# STM32L4R7 register map
File version: 2.0
CPU: CM4 r0p1, little endian, MPU, FPU, 4 interrupt priority bits
Registers are 32-bit, read-write, reset 0x0 unless marked. A register's access mark holds for its fields unless they carry their own. Offsets are from the block's base; [hi:lo] are bit positions; {n}, {i} and the like mark numbered series.

## PWR — Power control
Base 0x40007000
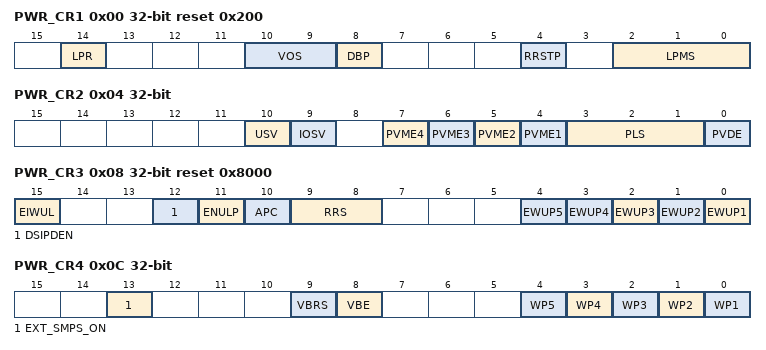
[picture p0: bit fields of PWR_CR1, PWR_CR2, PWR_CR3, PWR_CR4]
0x00 PWR_CR1 reset 0x200 — Power control register 1
  [14] LPR — Low-power run When this bit is set, the regulator is switched from main mode (MR) to low-power mode (LPR). Note: Stop 2 mode cannot be entered when LPR bit is set. Stop 1 is entered instead.
  [10:9] VOS — Voltage scaling range selection
    0=Cannot be written (forbidden by hardware); 1=Range 1; 2=Range 2; 3=Cannot be written (forbidden by hardware)
  [8] DBP — Disable backup domain write protection In reset state, the RTC and backup registers are protected against parasitic write access. This bit must be set to enable write access to these registers.
    0=Access to RTC and Backup registers disabled; 1=Access to RTC and Backup registers enabled
  [4] RRSTP — SRAM3 retention in Stop 2 mode
    0=SRAM3 is powered off in Stop 2 mode (SRAM3 content is lost); 1=SRAM3 is powered in Stop 2 mode (RAM3 content is kept)
  [2:0] LPMS — Low-power mode selection These bits select the low-power mode entered when CPU enters the Deepsleep mode. 1xx: Shutdown mode Note: If LPR bit is set, Stop 2 mode cannot be selected and Stop 1 mode shall be entered instead of Stop 2. Note: In Standby mode, SRAM2 can be preserved or not, depending on RRS bit configuration in PWR_CR3.
    0=Stop 0 mode; 1=Stop 1 mode; 2=Stop 2 mode; 3=Standby mode
0x04 PWR_CR2 — Power control register 2
  [10] USV — V<sub>DDUSB</sub> USB supply valid This bit is used to validate the V<sub>DDUSB</sub> supply for electrical and logical isolation purpose. Setting this bit is mandatory to use the USB OTG_FS peripheral. If V<sub>DDUSB</sub> is not always present in the application, the PVM can be used to determine whether this supply is ready or not.
    0=V<sub>DDUSB</sub> is not present. Logical and electrical isolation is applied to ignore this supply.; 1=V<sub>DDUSB</sub> is valid
  [9] IOSV — V<sub>DDIO2</sub> Independent I/Os supply valid This bit is used to validate the V<sub>DDIO2</sub> supply for electrical and logical isolation purpose. Setting this bit is mandatory to use PG[15:2]. If V<sub>DDIO2</sub> is not always present in the application, the PVM can be used to determine whether this supply is ready or not.
    0=V<sub>DDIO2</sub> is not present. Logical and electrical isolation is applied to ignore this supply.; 1=V<sub>DDIO2</sub> is valid
  [7] PVME4 — Peripheral voltage monitoring 4 enable: V<sub>DDA</sub> vs. 2.2V
    0=PVM4 (V<sub>DDA</sub> monitoring vs. 2.2V threshold) disable.; 1=PVM4 (V<sub>DDA</sub> monitoring vs. 2.2V threshold) enable.
  [6] PVME3 — Peripheral voltage monitoring 3 enable: V<sub>DDA</sub> vs. 1.62V
    0=PVM3 (V<sub>DDA</sub> monitoring vs. 1.62V threshold) disable.; 1=PVM3 (V<sub>DDA</sub> monitoring vs. 1.62V threshold) enable.
  [5] PVME2 — Peripheral voltage monitoring 2 enable: V<sub>DDIO2</sub> vs. 0.9V
    0=PVM2 (V<sub>DDIO2</sub> monitoring vs. 0.9V threshold) disable.; 1=PVM2 (V<sub>DDIO2</sub> monitoring vs. 0.9V threshold) enable.
  [4] PVME1 — Peripheral voltage monitoring 1 enable: V<sub>DDUSB</sub> vs. 1.2V
    0=PVM1 (V<sub>DDUSB</sub> monitoring vs. 1.2V threshold) disable.; 1=PVM1 (V<sub>DDUSB</sub> monitoring vs. 1.2V threshold) enable.
  [3:1] PLS — Power voltage detector level selection. These bits select the voltage threshold detected by the power voltage detector: Note: These bits are write-protected when the bit PVDL (PVD Lock) is set in the SYSCFG_CBR register. Note: These bits are reset only by a system reset.
    0=V<sub>PVD0</sub> around 2.0 V; 1=V<sub>PVD1</sub> around 2.2 V; 2=V<sub>PVD2</sub> around 2.4 V; 3=V<sub>PVD3</sub> around 2.5 V; 4=V<sub>PVD4</sub> around 2.6 V; 5=V<sub>PVD5</sub> around 2.8 V; 6=V<sub>PVD6</sub> around 2.9 V; 7=External input analog voltage PVD_IN (compared internally to VREFINT)
  [0] PVDE — Power voltage detector enable Note: This bit is write-protected when the bit PVDL (PVD Lock) is set in the SYSCFG_CBR register. Note: This bit is reset only by a system reset.
    0=Power voltage detector disable; 1=Power voltage detector enable
0x08 PWR_CR3 reset 0x8000 — Power control register 3
  [15] EIWUL — Enable internal wakeup line
    0=Internal wakeup line disable; 1=Internal wakeup line enable
  [12] DSIPDEN — Enable Pull-down activation on DSI pins
    1=Pull-Down is enabled on DSI pins; 0=Pull-Down is disabled on DSI pins
  [11] ENULP — Enable ULP sampling When this bit is set, the BORL, BORH and PVD are periodically sampled instead continuous monitoring to reduce power consumption. Fast supply drop between two sample/compare phases is not detected in this mode. This bit has impact only on STOP2, Standby and shutdown low power modes. Note: Available on STM32L4P5xx andSTM32L4Q5xx only.
  [10] APC — Apply pull-up and pull-down configuration When this bit is set, the I/O pull-up and pull-down configurations defined in the PWR_PUCRx and PWR_PDCRx registers are applied. When this bit is cleared, the PWR_PUCRx and PWR_PDCRx registers are not applied to the I/Os, instead the I/Os will be in floating mode during Standby or configured according GPIO controller GPIOx_PUPDR register during Run mode.
  [9:8] RRS — SRAM2 retention in Standby mode For STM32L4Rxxx and STM32L4Sxxx devices bit 9 is reserved For STM32L4P5xx and STM32L4Q5xx devices:
    0=SRAM2 is powered off in Standby mode (SRAM2 content is lost); 1=Full SRAM2 is powered by the low-power regulator in Standby mode (SRAM2 full content is kept); 2=Only 4 Kbytes of SRAM2 is powered by the low-power regulator in Standby mode (4 Kbytes of SRAM2 content is kept)
  [4] EWUP5 — Enable Wakeup pin WKUP5 When this bit is set, the external wakeup pin WKUP5 is enabled and triggers a wakeup from Standby or Shutdown event when a rising or a falling edge occurs.The active edge is configured via the WP5 bit in the PWR_CR4 register.
  [n-1] EWUP{n} (n=1..4) — Enable Wakeup pin WKUP{n} When this bit is set, the external wakeup pin WKUP{n} is enabled and triggers a wakeup from Standby or Shutdown event when a rising or a falling edge occurs. The active edge is configured via the WP{n} bit in the PWR_CR4 register.
0x0C PWR_CR4 — Power control register 4
  [13] EXT_SMPS_ON — external SMPS on. This bit informs the internal regulator about external SMPS switch status to decrease regulator output to 0.95 V in Range 2, allowing the external SMPS output down to 1.00 V. Note: This bit is only available on STM32L4P5xx and STM32L4Q5xx devices.
    0=the external SMPS switch is open; 1=the external SMPS switch is closed, internal regulator output is set to 0.95 V
  [9] VBRS — V<sub>BAT</sub> battery charging resistor selection
    0=Charge V<sub>BAT</sub> through a 5 kOhms resistor; 1=Charge V<sub>BAT</sub> through a 1.5 kOhms resistor
  [8] VBE — V<sub>BAT</sub> battery charging enable
    0=V<sub>BAT</sub> battery charging disable; 1=V<sub>BAT</sub> battery charging enable
  [n-1] WP{n} (n=1..5) — Wakeup pin WKUP{n} polarity This bit defines the polarity used for an event detection on external wake-up pin, WKUP{n}
    0=Detection on high level (rising edge); 1=Detection on low level (falling edge)
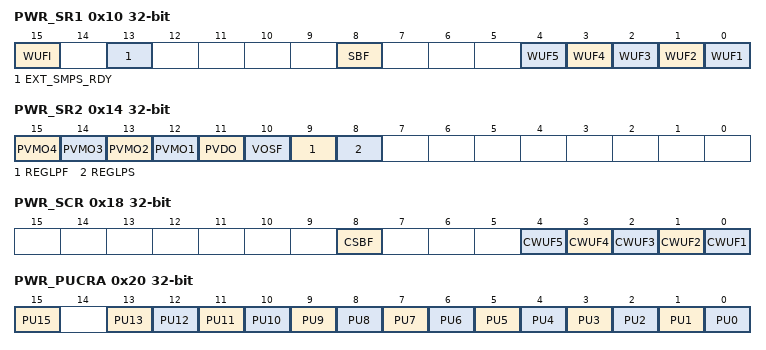
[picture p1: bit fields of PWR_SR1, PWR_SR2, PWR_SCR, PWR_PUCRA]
0x10 PWR_SR1 ro — Power status register 1
  [15] WUFI — Wakeup flag internal This bit is set when a wakeup is detected on the internal wakeup line. It is cleared when all internal wakeup sources are cleared.
  [13] EXT_SMPS_RDY — External SMPS ready This bit informs the state of regulator transition from Range 1 to Range 2 Note: This bit is only available on STM32L4P5xx and STM32L4Q5xx devices.
    0=Internal regulator not ready in Range 2, the external SMPS cannot be connected; 1=Internal regulator ready in Range 2, the external SMPS can be connected
  [8] SBF — Standby flag This bit is set by hardware when the device enters the Standby mode and is cleared by setting the CSBF bit in the PWR_SCR register, or by a power-on reset. It is not cleared by the system reset.
    0=The device did not enter the Standby mode; 1=The device entered the Standby mode
  [4] WUF5 — Wakeup flag 5 This bit is set when a wakeup event is detected on wakeup pin, WKUP5. It is cleared by writing 1 in the CWUF5 bit of the PWR_SCR register.
  [3] WUF4 — Wakeup flag 4 This bit is set when a wakeup event is detected on wakeup pin,WKUP4. It is cleared by writing 1 in the CWUF4 bit of the PWR_SCR register.
  [2] WUF3 — Wakeup flag 3 This bit is set when a wakeup event is detected on wakeup pin, WKUP3. It is cleared by writing 1 in the CWUF3 bit of the PWR_SCR register.
  [1] WUF2 — Wakeup flag 2 This bit is set when a wakeup event is detected on wakeup pin, WKUP2. It is cleared by writing 1 in the CWUF2 bit of the PWR_SCR register.
  [0] WUF1 — Wakeup flag 1 This bit is set when a wakeup event is detected on wakeup pin, WKUP1. It is cleared by writing 1 in the CWUF1 bit of the PWR_SCR register.
0x14 PWR_SR2 ro — Power status register 2
  [15] PVMO4 — Peripheral voltage monitoring output: V<sub>DDA</sub> vs. 2.2 V Note: PVMO4 is cleared when PVM4 is disabled (PVME4 = 0). After enabling PVM4, the PVM4 output is valid after the PVM4 wakeup time.
    0=V<sub>DDA</sub> voltage is above PVM4 threshold (around 2.2 V); 1=V<sub>DDA</sub> voltage is below PVM4 threshold (around 2.2 V)
  [14] PVMO3 — Peripheral voltage monitoring output: V<sub>DDA</sub> vs. 1.62 V Note: PVMO3 is cleared when PVM3 is disabled (PVME3 = 0). After enabling PVM3, the PVM3 output is valid after the PVM3 wakeup time.
    0=V<sub>DDA</sub> voltage is above PVM3 threshold (around 1.62 V); 1=V<sub>DDA</sub> voltage is below PVM3 threshold (around 1.62 V)
  [13] PVMO2 — Peripheral voltage monitoring output: V<sub>DDIO2</sub> vs. 0.9 V Note: PVMO2 is cleared when PVM2 is disabled (PVME2 = 0). After enabling PVM2, the PVM2 output is valid after the PVM2 wakeup time.
    0=V<sub>DDIO2</sub> voltage is above PVM2 threshold (around 0.9 V); 1=V<sub>DDIO2</sub> voltage is below PVM2 threshold (around 0.9 V)
  [12] PVMO1 — Peripheral voltage monitoring output: V<sub>DDUSB</sub> vs. 1.2 V Note: PVMO1 is cleared when PVM1 is disabled (PVME1 = 0). After enabling PVM1, the PVM1 output is valid after the PVM1 wakeup time.
    0=V<sub>DDUSB</sub> voltage is above PVM1 threshold (around 1.2 V); 1=V<sub>DDUSB</sub> voltage is below PVM1 threshold (around 1.2 V)
  [11] PVDO — Power voltage detector output
    0=V<sub>DD</sub> is above the selected PVD threshold; 1=V<sub>DD</sub> is below the selected PVD threshold
  [10] VOSF — Voltage scaling flag A delay is required for the internal regulator to be ready after the voltage scaling has been changed. VOSF indicates that the regulator reached the voltage level defined with VOS bits of the PWR_CR1 register.
    0=The regulator is ready in the selected voltage range; 1=The regulator output voltage is changing to the required voltage level
  [9] REGLPF — Low-power regulator flag This bit is set by hardware when the MCU is in Low-power run mode. When the MCU exits from the Low-power run mode, this bit remains at 1 until the regulator is ready in main mode. A polling on this bit must be done before increasing the product frequency. This bit is cleared by hardware when the regulator is ready.
    0=The regulator is ready in main mode (MR); 1=The regulator is in low-power mode (LPR)
  [8] REGLPS — Low-power regulator started This bit provides the information whether the low-power regulator is ready after a power-on reset or a Standby/Shutdown. If the Standby mode is entered while REGLPS bit is still cleared, the wakeup from Standby mode time may be increased.
    0=The low-power regulator is not ready; 1=The low-power regulator is ready
0x18 PWR_SCR wo — Power status clear register
  [8] CSBF — Clear standby flag Setting this bit clears the SBF flag in the PWR_SR1 register.
  [n-1] CWUF{n} (n=1..5) — Clear wakeup flag {n} Setting this bit clears the WUF{n} flag in the PWR_SR1 register.
0x20 PWR_PUCRA — Power Port A pull-up control register
  [15] PU15 — Port A pull-up bit 15 When set, this bit activates the pull-up on PA[15] when APC bit is set in PWR_CR3 register. If the corresponding PD15 bit is also set, the pull-up is not activated and the pull-down is activated instead with highest priority.
  [n] PU{n} (n=0..13) — Port A pull-up bit y (y=0...13) When set, this bit activates the pull-up on PA[y] when APC bit is set in PWR_CR3 register. The pull-up is not activated if the corresponding PDy bit is also set.
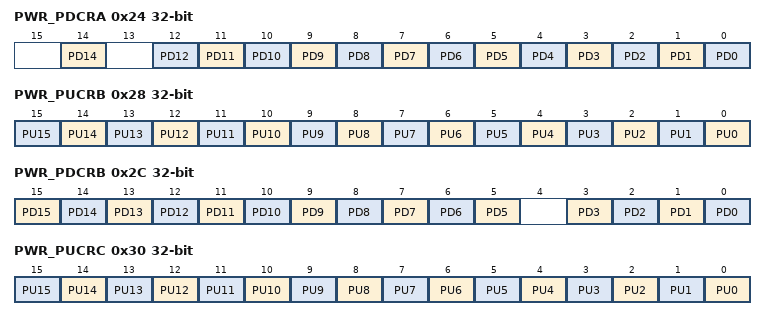
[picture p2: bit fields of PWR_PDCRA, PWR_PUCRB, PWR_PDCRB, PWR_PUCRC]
0x24 PWR_PDCRA — Power Port A pull-down control register
  [14] PD14 — Port A pull-down bit 14 When set, this bit activates the pull-down on PA[14] when APC bit is set in PWR_CR3 register.
  [n] PD{n} (n=0..12) — Port A pull-down bit y (y=0..12) When set, this bit activates the pull-down on PA[y] when APC bit is set in PWR_CR3 register.
0x28 PWR_PUCRB — Power Port B pull-up control register
  [n] PU{n} (n=0..15) — Port B pull-up bit y (y=0..15) When set, this bit activates the pull-up on PB[y] when APC bit is set in PWR_CR3 register. The pull-up is not activated if the corresponding PDy bit is also set.
0x2C PWR_PDCRB — Power Port B pull-down control register
  [n] PD{n} (n=5..15) — Port B pull-down bit y (y=5..15) When set, this bit activates the pull-down on PB[y] when APC bit is set in PWR_CR3 register.
  [n] PD{n} (n=0..3) — Port B pull-down bit y (y=0..3) When set, this bit activates the pull-down on PB[y] when APC bit is set in PWR_CR3 register.
0x30 PWR_PUCRC — Power Port C pull-up control register
  [n] PU{n} (n=0..15) — Port C pull-up bit y (y=0..15) When set, this bit activates the pull-up on PC[y] when APC bit is set in PWR_CR3 register. The pull-up is not activated if the corresponding PDy bit is also set.
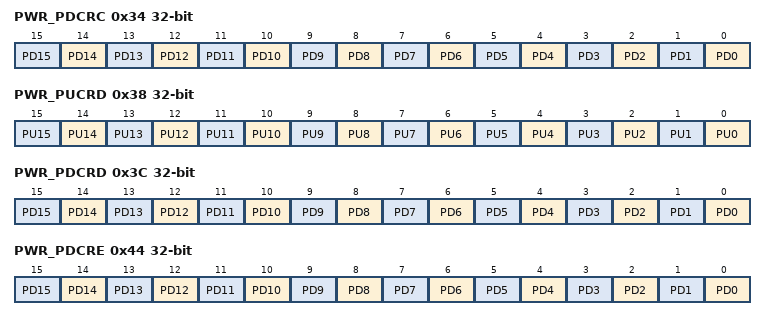
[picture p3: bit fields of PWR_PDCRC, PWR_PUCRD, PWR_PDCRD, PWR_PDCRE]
0x34 PWR_PDCRC — Power Port C pull-down control register
  [n] PD{n} (n=0..15) — Port C pull-down bit y (y=0..15) When set, this bit activates the pull-down on PC[y] when APC bit is set in PWR_CR3 register.
0x38 PWR_PUCRD — Power Port D pull-up control register
  [n] PU{n} (n=0..15) — Port D pull-up bit y (y=0..15) When set, this bit activates the pull-up on PD[y] when APC bit is set in PWR_CR3 register. The pull-up is not activated if the corresponding PDy bit is also set.
0x3C PWR_PDCRD — Power Port D pull-down control register
  [n] PD{n} (n=0..15) — Port D pull-down bit y (y=0..15) When set, this bit activates the pull-down on PD[y] when APC bit is set in PWR_CR3 register.
0x44 PWR_PDCRE — Power Port E pull-down control register
  [n] PD{n} (n=0..15) — Port E pull-down bit y (y=0..15) When set, this bit activates the pull-down on PE[y] when APC bit is set in PWR_CR3 register.
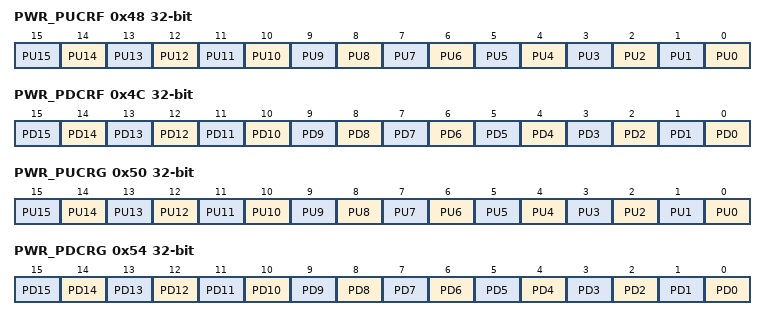
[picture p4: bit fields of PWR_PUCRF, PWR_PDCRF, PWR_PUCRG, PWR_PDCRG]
0x48 PWR_PUCRF — Power Port F pull-up control register
  [n] PU{n} (n=0..15) — Port F pull-up bit y (y=0..15) When set, this bit activates the pull-up on PF[y] when APC bit is set in PWR_CR3 register. The pull-up is not activated if the corresponding PDy bit is also set.
0x4C PWR_PDCRF — Power Port F pull-down control register
  [n] PD{n} (n=0..15) — Port F pull-down bit y (y=0..15) When set, this bit activates the pull-down on PF[y] when APC bit is set in PWR_CR3 register.
0x50 PWR_PUCRG — Power Port G pull-up control register
  [n] PU{n} (n=0..15) — Port G pull-up bit y (y=0..15) When set, this bit activates the pull-up on PG[y] when APC bit is set in PWR_CR3 register. The pull-up is not activated if the corresponding PDy bit is also set.
0x54 PWR_PDCRG — Power Port G pull-down control register
  [n] PD{n} (n=0..15) — Port G pull-down bit y (y=0..15) When set, this bit activates the pull-down on PG[y] when APC bit is set in PWR_CR3 register.
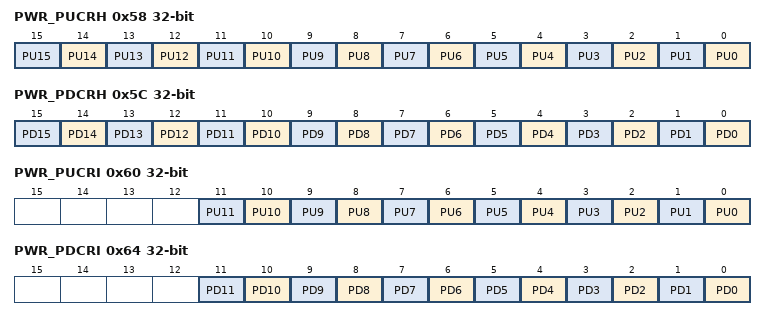
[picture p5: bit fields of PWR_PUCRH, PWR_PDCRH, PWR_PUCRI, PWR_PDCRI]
0x58 PWR_PUCRH — Power Port H pull-up control register
  [n] PU{n} (n=0..15) — Port H pull-up bit y (y=0..15) When set, this bit activates the pull-up on PH[y] when APC bit is set in PWR_CR3 register. The pull-up is not activated if the corresponding PDy bit is also set.
0x5C PWR_PDCRH — Power Port H pull-down control register
  [n] PD{n} (n=0..15) — Port H pull-down bit x (y =15...0) When set, this bit activates the pull-down on PH[y] when APC bit is set in PWR_CR3 register.
0x60 PWR_PUCRI — Power Port I pull-up control register
  [n] PU{n} (n=0..11) — Port I pull-up bit y (y=0..11) When set, this bit activates the pull-up on PI[y] when APC bit is set in PWR_CR3 register. The pull-up is not activated if the corresponding PDy bit is also set.
0x64 PWR_PDCRI — Power Port I pull-down control register
  [n] PD{n} (n=0..11) — Port I pull-down bit y (y=0..11) When set, this bit activates the pull-down on PI[y] when APC bit is set in PWR_CR3 register.
0x80 PWR_CR5 reset 0x100 — PWR control register
  [8] R1MODE — Main regulator Range 1 mode This bit is only valid for the main regulator in Range 1 and has no effect on Range 2. It is recommended to reset this bit when the system frequency is greater than 80 MHz. Refer to Table 28: Range 1 boost mode configuration.
    0=Main regulator in Range 1 boost mode; 1=Main regulator in Range 1 normal mode

## Notices in the file
Copyright (c) 2023 STMicroelectronics.
SPDX-License-Identifier: Apache-2.0
Licensed under the Apache License, Version 2.0 (the "License");
you may not use this file except in compliance with the License.
You may obtain a copy of the License at
http://www.apache.org/licenses/LICENSE-2.0
Unless required by applicable law or agreed to in writing, software
distributed under the License is distributed on an "AS IS" BASIS,
WITHOUT WARRANTIES OR CONDITIONS OF ANY KIND, either express or implied.
See the License for the specific language governing permissions and
limitations under the License.
